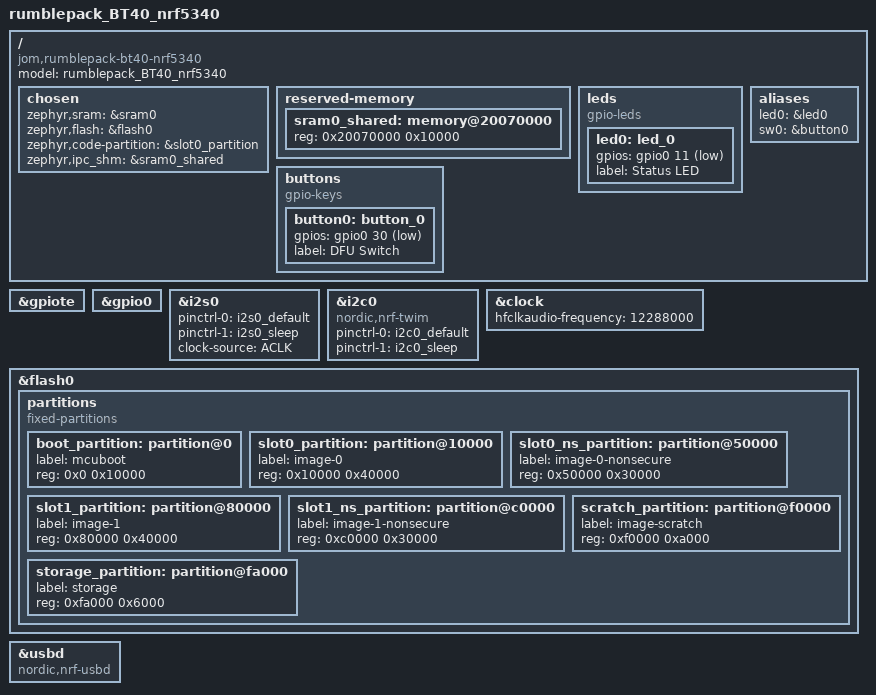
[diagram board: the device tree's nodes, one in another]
// Copyright (c) 2023 Nordic Semiconductor ASA
// SPDX-License-Identifier: Apache-2.0

/dts-v1/;
#include <nordic/nrf5340_cpuapp_qkaa.dtsi>
#include "rumblepack_bt40_nrf5340-pinctrl.dtsi"

/ {
	model = "rumblepack_BT40_nrf5340";
	compatible = "jom,rumblepack-bt40-nrf5340";

	chosen {
		zephyr,sram = &sram0;
		zephyr,flash = &flash0;
		zephyr,code-partition = &slot0_partition;
        zephyr,ipc_shm = &sram0_shared;
    };
	
    reserved-memory {
        #address-cells = <1>;
        #size-cells = <1>;
        ranges;


        //sram0_ns: image_ns@20000000 {
            /* Non-Secure image memory */
        //};
        sram0_shared: memory@20070000 {
            /* SRAM allocated to shared memory */
            reg = <0x20070000 0x10000>;
        };
    };

	leds {
		compatible = "gpio-leds";

		led0: led_0 {
			gpios = < &gpio0 11 GPIO_ACTIVE_LOW >;
			label = "Status LED";
		};
	};

	buttons {
		compatible = "gpio-keys";

		button0: button_0 {
			gpios = < &gpio0 30 (GPIO_PULL_UP | GPIO_ACTIVE_LOW) >;
			label = "DFU Switch";
		};
	};

	aliases {
		led0 = &led0;
		sw0 = &button0;
	};
};

&gpiote {
	status = "okay";
};

&gpio0 {
	status = "okay";
};

&i2s0 {
	status = "okay";
	pinctrl-0 = <&i2s0_default>;
	pinctrl-1 = <&i2s0_sleep>;
	pinctrl-names = "default", "sleep";
	clock-source = "ACLK";
};

&i2c0 {
	compatible = "nordic,nrf-twim";
	status = "okay";
	pinctrl-0 = <&i2c0_default>;
	pinctrl-1 = <&i2c0_sleep>;
	pinctrl-names = "default", "sleep";
};

&clock {
	hfclkaudio-frequency = < 12288000 >;
};


&flash0 {
	partitions {
		compatible = "fixed-partitions";
		#address-cells = <1>;
		#size-cells = <1>;

		boot_partition: partition@0 {
			label = "mcuboot";
			reg = <0x0 0x10000>;
		};
		slot0_partition: partition@10000 {
			label = "image-0";
			reg = <0x10000 0x40000>;
		};
		slot0_ns_partition: partition@50000 {
			label = "image-0-nonsecure";
			reg = <0x50000 0x30000>;
		};
		slot1_partition: partition@80000 {
			label = "image-1";
			reg = <0x80000 0x40000>;
		};
		slot1_ns_partition: partition@c0000 {
			label = "image-1-nonsecure";
			reg = <0xc0000 0x30000>;
		};
		scratch_partition: partition@f0000 {
			label = "image-scratch";
			reg = <0xf0000 0xa000>;
		};
		storage_partition: partition@fa000 {
			label = "storage";
			reg = <0xfa000 0x6000>;
		};
	};
};

zephyr_udc0: &usbd {
	compatible = "nordic,nrf-usbd";
	status = "okay";
};

